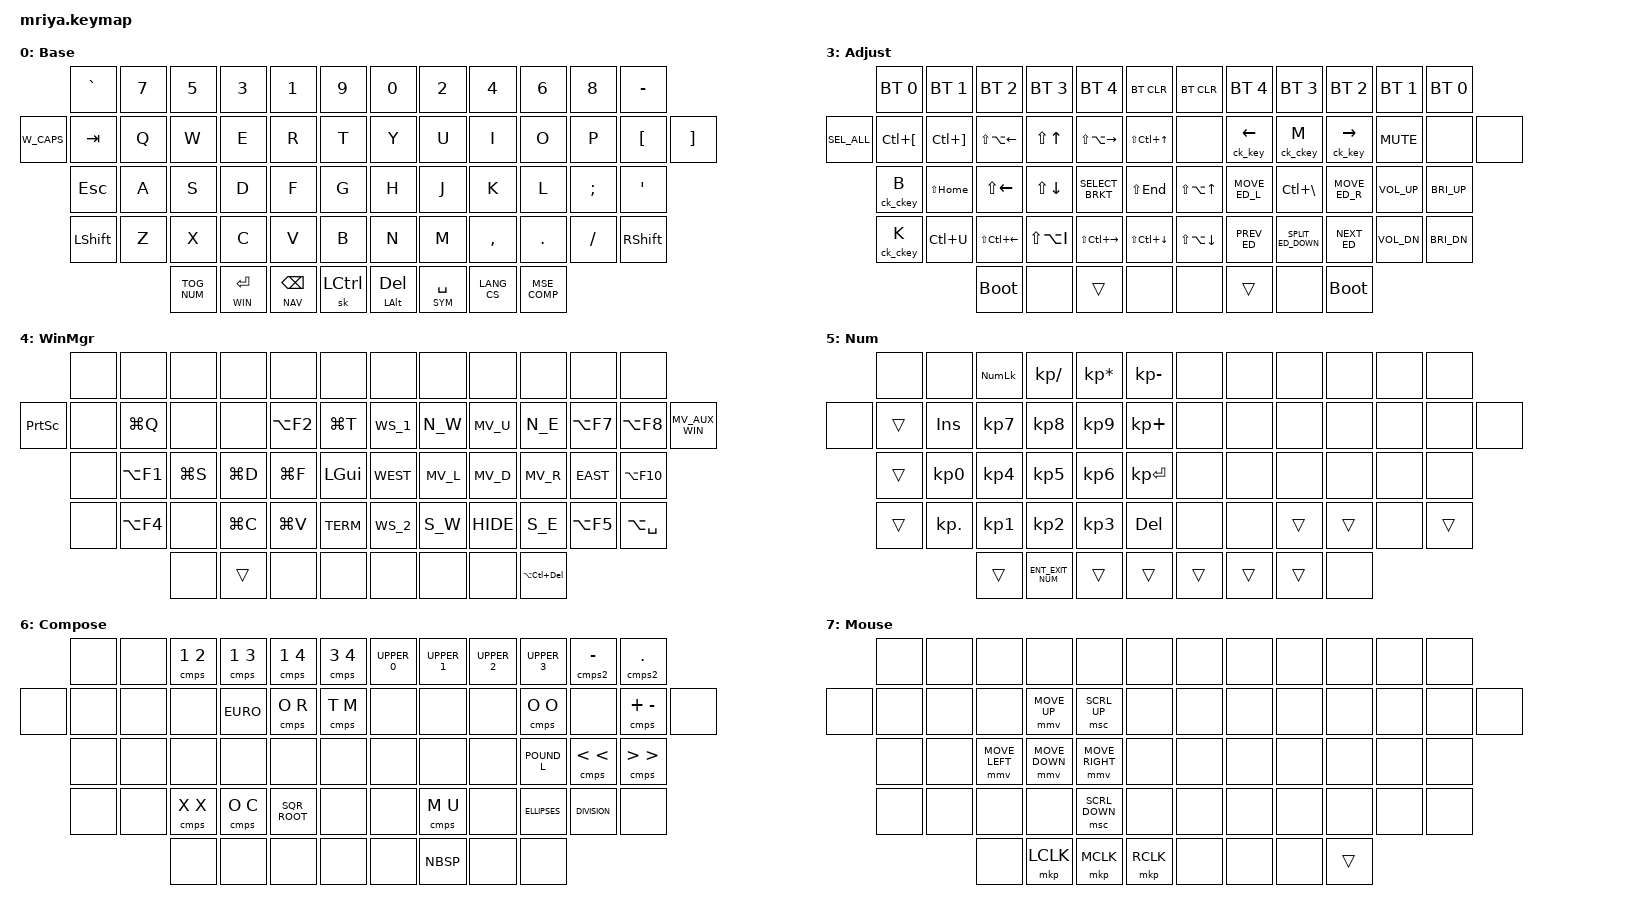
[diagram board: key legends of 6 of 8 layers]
/*
 * Copyright (c) 2023-2024 serg3295
 *
 * SPDX-License-Identifier: MIT
 */

#include <behaviors.dtsi>
#include <dt-bindings/zmk/bt.h>
#include <dt-bindings/zmk/keys.h>
#include <dt-bindings/zmk/mouse.h>
#include <dt-bindings/zmk/pointing.h>

#define DEF  0
#define NAV  1
#define SYM  2
#define ADJ  3
#define WIN  4
#define NUM  5
#define COMP 6
#define MOUSE 7

#include "actions.h"
#include "macros.dtsi"

&lt {
  tapping_term_ms = <250>;
  quick_tap_ms = <250>;
};

&mt {
  tapping_term_ms = <250>;
  quick_tap_ms = <250>;
};

/ {
    conditional_layers {
        compatible = "zmk,conditional-layers";
        tri_layer {
            if-layers = <NAV SYM>;
            then-layer = <ADJ>;
        };
    };

    behaviors {
      // hold-tap
      ht3: ht_300ms {
        compatible = "zmk,behavior-hold-tap";
        #binding-cells = <2>;
        flavor = "tap-preferred";
        tapping-term-ms = <300>;
        bindings = <&kp>, <&kp>;
      };

      ht_caps: mod_caps {
        compatible = "zmk,behavior-hold-tap";
        #binding-cells = <2>;
        flavor = "tap-preferred";
        tapping-term-ms = <300>;
        bindings = <&kp>, <&caps_word>;
      };

      ht_not_eq: ht_not_equal {
        compatible = "zmk,behavior-hold-tap";
        #binding-cells = <2>;
        flavor = "tap-preferred";
        tapping-term-ms = <300>;
        bindings = <&not_eq>, <&kp>;
      };

      ht_ru: ht_ru {
        compatible = "zmk,behavior-hold-tap";
        #binding-cells = <2>;
        flavor = "tap-preferred";
        tapping-term-ms = <200>;
        bindings = <&ru>, <&kp>;
      };

      ht_ru2: ht_ru2 {
        compatible = "zmk,behavior-hold-tap";
        #binding-cells = <2>;
        flavor = "tap-preferred";
        tapping-term-ms = <200>;
        bindings = <&ru2>, <&kp>;
      };

      ht_ckk: ht_ctrl_k_keycode {
        compatible = "zmk,behavior-hold-tap";
        #binding-cells = <2>;
        flavor = "tap-preferred";
        tapping-term-ms = <300>;
        bindings = <&ck_key>, <&kp>;
      };

      ht_ck_ck: ht_ctrl_k_ctrl_k {
        compatible = "zmk,behavior-hold-tap";
        #binding-cells = <2>;
        flavor = "tap-preferred";
        tapping-term-ms = <300>;
        bindings = <&ck_key>, <&ck_key>;
      };

      ht_sk_kp: ht_sk_kp {
        compatible = "zmk,behavior-hold-tap";
        #binding-cells = <2>;
        flavor = "tap-preferred";
        tapping-term-ms = <300>;
        bindings = <&sk>, <&kp>;
      };

      mo_sl: mo_sl {
        compatible = "zmk,behavior-hold-tap";
        #binding-cells = <2>;
        flavor = "hold-preferred";
        tapping-term-ms = <300>;
        bindings = <&mo>, <&sl>;
      };

      // tap-dance
      fold: fold {
        compatible = "zmk,behavior-tap-dance";
        #binding-cells = <0>;
        tapping-term-ms = <200>;
        bindings = <&ht_ckk LC(N0) LC(LS(LBKT))>, <&ck_key LC(LBKT)>;
      };
      unfold: unfold {
        compatible = "zmk,behavior-tap-dance";
        #binding-cells = <0>;
        tapping-term-ms = <200>;
        bindings = <&ht_ckk LC(J) LC(LS(RBKT))>, <&ck_key LC(RBKT)>;
      };

      td_home: home_actions {
        compatible = "zmk,behavior-tap-dance";
        #binding-cells = <0>;
        tapping-term-ms = <300>;
        bindings = <&ht3 LC(HOME) HOME>, <&kp LC(LA(UP))>;
      };
      td_end: end_actions {
        compatible = "zmk,behavior-tap-dance";
        #binding-cells = <0>;
        tapping-term-ms = <300>;
        bindings = <&ht3 LC(END) END>, <&kp LC(LA(DOWN))>;
      };

      td_defs: defs_actions {
        compatible = "zmk,behavior-tap-dance";
        #binding-cells = <0>;
        tapping-term-ms = <300>;
        bindings = <&ht_ckk F12 F12>, <&kp LA(F12)>;
      };

      // toggle layer
       tog_on: toggle_layer_on_only {
          compatible = "zmk,behavior-toggle-layer";
          #binding-cells = <1>;
          display-name = "Toggle Layer On";
          toggle-mode = "on";
      };

      tog_off: toggle_layer_off_only {
          compatible = "zmk,behavior-toggle-layer";
          #binding-cells = <1>;
          display-name = "Toggle Layer Off";
          toggle-mode = "off";
      };

      tog_l: toggle_layer_specifically {
        compatible = "zmk,behavior-hold-tap";
        #binding-cells = <2>;
        flavor = "tap-preferred";
        tapping-term-ms = <300>;
        bindings = <&tog_on>, <&tog_off>;
      };
    };

    keymap {
      compatible = "zmk,keymap";
      default_layer {
        display-name = "Base";
        bindings = <
                  &kp GRAVE   &kp N7  &kp N5   &kp N3       &kp N1        &kp N9          &kp N0        &kp N2         &kp N4     &kp N6   &kp N8         &kp MINUS
          W_CAPS  &kp TAB     &kp Q   &kp W    &kp E        &kp R         &kp T           &kp Y         &kp U          &kp I      &kp O    &kp P          &kp LEFT_BRACKET  &kp RIGHT_BRACKET
                  &kp ESC     &kp A   &kp S    &kp D        &kp F         &kp G           &kp H         &kp J          &kp K      &kp L    &kp SEMICOLON  &kp SINGLE_QUOTE
                  &kp LSHIFT  &kp Z   &kp X    &kp C        &kp V         &kp B           &kp N         &kp M          &kp COMMA  &kp DOT  &kp FSLH       &kp RSHIFT
                                      TOG_NUM  &lt WIN RET  &lt NAV BSPC  &sk LCTRL       &mt LALT DEL  &lt SYM SPACE  LANG_CS    MSE_COMP
        >;
      };

      nav_layer {
        display-name = "Nav";
        bindings = <
                  GO_BACK    &kp F7           &kp F5       &kp F3      &kp F1       &kp F9         &ht_ckk F10 F10  &kp F2  &kp F4   &kp F6   &kp F8        GO_FWD
          VSTERM  &kp PG_UP  &kp LS(LC(TAB))  &kp LC(TAB)  &kp UP      &kp INS      &kp F11        &td_defs         REFS    JUMP_UP  HOVER    &kp LS(F10)   PREV_DIFF  NEXT_DIFF
                  &kp PG_DN  &td_home         &kp LEFT     &kp DOWN    &kp RIGHT    &td_end        &mv_line UP      JUMP_L  JUMP_DN  JUMP_R   F_BSPC        F_DEL
                  &trans     &kp SPACE        &kp LS(DEL)  &kp LC(INS) &kp LS(INS)  &kp DEL        &mv_line DOWN    &fold   COPY_LN  &unfold  &kp LS(LA(G)) &trans
                                              &none        &none       &trans       &trans         &trans           &trans  &trans   &trans
        >;
      };

      sym_layer {
        display-name = "Sym";
        bindings = <
                      &ru GRAVE   &trans     &trans    &trans     &trans    &trans           &trans     &trans    &trans     &trans       &trans    &none
          &transform  &ru2 GRAVE  &kp GRAVE  LT_RU     NEQ_EXCL   GT_RU     &kp EXCL         &kp PRCNT  LBKT_RU   HASH_RU    RBKT_RU      &ru N3    SHEBANG  &kp RGUI
                      AT_RU       &kp UNDER  &kp LPAR  &kp MINUS  &kp RPAR  CARET_RU         DLLR_RU    LBRC_RU   &kp PLUS   RBRC_RU      &kp BSLH  &kp DOUBLE_QUOTES
                      &trans      &kp SPACE  PIPE_RU   NEQ_TILDE  AMPS_RU   &none            DBL_COLON  &kp STAR  &kp COMMA  &key_repeat  FSLH_RU   &trans
                                  &none      &trans    &trans     &trans                     &trans     &trans    &none      &none
        >;
      };

      adjust_layer {
        display-name = "Adjust";
        bindings = <
                    &bt BT_SEL 0  &bt BT_SEL 1  &bt BT_SEL 2     &bt BT_SEL 3  &bt BT_SEL 4      &bt BT_CLR           &bt BT_CLR        &bt BT_SEL 4  &bt BT_SEL 3   &bt BT_SEL 2  &bt BT_SEL 1   &bt BT_SEL 0
          SEL_ALL   &kp LC(LBKT)  &kp LC(RBKT)  &kp LS(LA(LEFT)) &kp LS(UP)    &kp LS(LA(RIGHT)) &kp LS(LC(UP))       &none             &ck_key LEFT  &ck_ckey M     &ck_key RIGHT &kp C_MUTE     &none         &none
                    &ck_ckey B    &kp LS(HOME)  &kp LS(LEFT)     &kp LS(DOWN)  SELECT_BRKT       &kp LS(END)          &kp LS(LA(UP))    MOVE_ED_L     &kp LC(BSLH)   MOVE_ED_R     &kp C_VOL_UP   &kp C_BRI_UP
                    &ck_ckey K    &kp LC(U)     &kp LS(LC(LEFT)) &kp LS(LA(I)) &kp LS(LC(RIGHT)) &kp LS(LC(DOWN))     &kp LS(LA(DOWN))  PREV_ED       SPLIT_ED_DOWN  NEXT_ED       &kp C_VOL_DN   &kp C_BRI_DN
                                                &bootloader      &none         &trans            &none                &none             &trans        &none          &bootloader
        >;
      };

      win_layer {
        display-name = "WinMgr";
        bindings = <
                    &none  &none       &none      &none      &none       &none           &none  &none  &none  &none  &none       &none
          &kp PSCRN &none  &kp LG(Q)   &none      &none      &kp LA(F2)  &kp LG(T)       WS_1   N_W    MV_U   N_E    &kp LA(F7)  &kp LA(F8)  MV_AUX_WIN
                    &none  &kp LA(F1)  &kp LG(S)  &kp LG(D)  &kp LG(F)   &kp LGUI        WEST   MV_L   MV_D   MV_R   EAST        &kp LA(F10)
                    &none  &kp LA(F4)  &none      &kp LG(C)  &kp LG(V)   TERM            WS_2   S_W    HIDE   S_E    &kp LA(F5)  &kp LA(SPACE)
                                       &none      &trans     &none       &none           &none  &none  &none  &kp LA(LC(DEL))
        >;
      };

      num_layer {
        display-name = "Num";
        bindings = <
                &none   &none       &kp KP_NLCK  &kp KP_DIVIDE  &kp KP_MULTIPLY  &kp KP_MINUS     &none  &none  &none   &none   &none   &none
          &none &trans  &kp INS     &kp KP_N7    &kp KP_N8      &kp KP_N9        &kp KP_PLUS      &none  &none  &none   &none   &none   &none  &none
                &trans  &kp KP_N0   &kp KP_N4    &kp KP_N5      &kp KP_N6        &kp KP_ENTER     &none  &none  &none   &none   &none   &none
                &trans  &kp KP_DOT  &kp KP_N1    &kp KP_N2      &kp KP_N3        &kp DEL          &none  &none  &trans  &trans  &none   &trans
                                    &trans       ENT_EXIT_NUM   &trans           &trans           &trans  &trans  &trans  &none
        >;
      };

      comp_layer {
        display-name = "Compose";
        bindings = <
                &none  &none  &cmps N1 N2  &cmps N1 N3  &cmps N1 N4  &cmps N3 N4       UPPER_0  UPPER_1    UPPER_2   UPPER_3    &cmps2 MINUS  &cmps2 DOT
         &none  &none  &none  &none        EURO         &cmps O R    &cmps T M         &none    &none      &none     &cmps O O  &none         &cmps PLUS MINUS  &none
                &none  &none  &none        &none        &none        &none             &none    &none      &none     POUND_L    &cmps LT LT   &cmps GT GT
                &none  &none  &cmps X X    &cmps O C    SQR_ROOT     &none             &none    &cmps M U  &none     ELLIPSES   DIVISION      &none
                              &none        &none        &none        &none             &none    NBSP       &none     &none
        >;
      };

      mouse_layer {
        display-name = "Mouse";
        bindings = <
                &none  &none  &none          &none          &none           &none            &none  &none  &none  &none  &none  &none
          &none &none  &none  &none          &mmv MOVE_UP   &msc SCRL_UP    &none            &none  &none  &none  &none  &none  &none  &none
                &none  &none  &mmv MOVE_LEFT &mmv MOVE_DOWN &mmv MOVE_RIGHT &none            &none  &none  &none  &none  &none  &none
                &none  &none  &none          &none          &msc SCRL_DOWN  &none            &none  &none  &none  &none  &none  &none
                              &none          &mkp LCLK      &mkp MCLK       &mkp RCLK        &none  &none  &none  &trans
        >;
      };
    };
};
